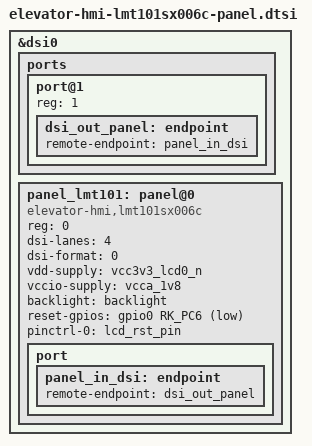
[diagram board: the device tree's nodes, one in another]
// SPDX-License-Identifier: (GPL-2.0 OR MIT)
/*
 * LMT101SX006C + JD9365DA-H3 (jadard) on RK3566 MIPI-DSI controller **dsi0**.
 *
 * Replaces the stock EVB `simple-panel-dsi` `panel@0` under &dsi0 from
 * rk3568-evb.dtsi (same graph pattern: panel endpoint + &dsi0/ports/port@1).
 *
 * Phandle alignment (BSP tree at linux-rockchip_6.1 SRCREV, files
 * arch/arm64/boot/dts/rockchip/rk3566-evb2-lp4x-v10.dtsi + rk3568-evb.dtsi):
 *   vcc3v3_lcd0_n — VCC3V3_LCD rail; EM3566 v3 enables via PWM0_M0 / GPIO0_B7 (board DTS)
 *   vcca_1v8 — rk809 PMIC LDO in rk3568-evb.dtsi (panel IO / VCCIO)
 *   backlight — pwm-backlight node in rk3568-evb.dtsi
 *
 * In-repo carrier docs (signal names, not alternate phandles):
 *   library/EM3566/Usermanual/EM3566_hardware_manual.md §2.8 CON1
 *   library/EM3566/Schematic/em3566_v3sch.md
 *
 * BLK-006 / TASK-121: reset-gpios on gpio0 RK_PC6 (TOUCH_RST / CON1 pin 11,
 * SoM pin 138) — **gpiochip0 line 22**, **GPIO_ACTIVE_LOW** per vendor Q1.
 * Board DTS disables **&spi0** so SPI0_CS0 does not hold PC6 low. FPC RESET
 * (pin 5) must route to CON1 pin 11. `gt1x` disabled in board DTS.
 * TASK-125: vendor init — **4-lane DSI** (`{0x80,0x03}` CMD_DSI_INT0 bits[1:0]=11; `library/LMT101/LMT101SX006C initial codes.txt`).
 */

#include <dt-bindings/gpio/gpio.h>
#include <dt-bindings/pinctrl/rockchip.h>

&dsi0 {
	/*
	 * 2026-07-03: `rockchip,lane-rate = <420>` REMOVED again (owner direction:
	 * revert to the one state proven to give clean DIAG15 register reads,
	 * before drawing any further hardware conclusion). Without this
	 * property the driver falls back to pixel_clock * (bpp/lanes) * 10/9 =
	 * ~468 Mbps (dw_mipi_dsi_calculate_lane_mpbs() in
	 * dw-mipi-dsi-rockchip.c never inspects mode_flags -- confirmed by
	 * direct source read). This is NOT the vendor's stated PLL_CLOCK=420
	 * (library/LMT101/LMT101SX006C initial codes.txt) -- that mismatch is
	 * accepted for now in exchange for reliable diagnostics.
	 *
	 * History: this property was added, then removed ("revert-step-a"),
	 * then re-added today ("kill test", commit 769e5a0) to test vendor-rate
	 * parity now that BIST (patch 0020) was confirmed as a separate,
	 * unrelated confound. Result: `-110` DCS-read timeouts persisted at
	 * 420 Mbps even with BIST absent and even with/without the TASK-141
	 * XRES pinctrl fix present -- see diary/SESSION-LOG.md 2026-07-03 for
	 * the full isolation chain across all four combinations tested. No
	 * single-variable root cause was isolated. Meanwhile every build
	 * WITHOUT this property (468 Mbps, driver-calculated) has produced
	 * clean reads every single time tested (0x0A=0x1c, 0x0F=0xC0,
	 * 0x45=0x00, ID=0x93) -- most recently confirmed 2026-07-03.
	 *
	 * Do not re-add this property without a new, explicit reason -- vendor
	 * PLL_CLOCK=420 parity is a documented, accepted, deliberate deviation
	 * while this investigation is open, not an oversight.
	 */

	/delete-node/ panel@0;

	ports {
		/delete-node/ port@1;

		port@1 {
			reg = <1>;
			dsi_out_panel: endpoint {
				remote-endpoint = <&panel_in_dsi>;
			};
		};
	};

	panel_lmt101: panel@0 {
		compatible = "elevator-hmi,lmt101sx006c", "jadard,jd9365da-h3";
		reg = <0>;
		dsi-lanes = <4>;
		dsi-format = <0>;
		vdd-supply = <&vcc3v3_lcd0_n>;
		vccio-supply = <&vcca_1v8>;
		backlight = <&backlight>;
		reset-gpios = <&gpio0 RK_PC6 GPIO_ACTIVE_LOW>;
		/*
		 * TASK-141: max drive strength + pull-up on XRES (lcd_rst_pin in board
		 * DTS). RETAINED PERMANENTLY — owner confirmed this configuration is
		 * bulletproof/reliable (2026-07-03), and it predates the 420 Mbps
		 * change. Do not remove or test removal of this property again
		 * without new physical (scope/multimeter) evidence directly
		 * implicating it; a prior isolation test that removed this property
		 * to chase a BTA -110 (ETIMEDOUT) DIAG15-read symptom was withdrawn
		 * per owner direction — see diary/SESSION-LOG.md 2026-07-03 "reset
		 * pin bulletproof" entry.
		 *
		 * Context for future readers: the -110 DIAG15 read-timeout symptom
		 * (seen on some 420 Mbps + this-pinctrl builds) does NOT change the
		 * standing BLK-014 diagnosis either way -- builds with successful
		 * reads (0x0A=0x1c, 0x45=0x00) and builds with -110 timeouts both
		 * show the panel's analog boost (AVDD/AVEE/VGH/VGL) never starting.
		 * Whether the debug register read itself succeeds or times out is a
		 * secondary instrumentation detail, not the root blocker. Root
		 * blocker remains hardware (VDDIN inrush, BL 9.6V, MIPI lane scope,
		 * TASK-137 spare-panel swap) per AGENTS.md TASK-140 gate.
		 */
		pinctrl-names = "default";
		pinctrl-0 = <&lcd_rst_pin>;

		port {
			panel_in_dsi: endpoint {
				remote-endpoint = <&dsi_out_panel>;
			};
		};
	};
};
